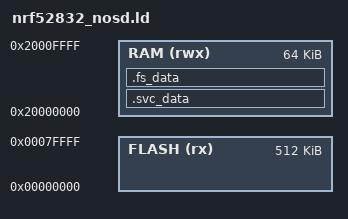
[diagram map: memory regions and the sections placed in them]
/* 无 SoftDevice / 无 bootloader：app 直接从 0x0 启动（nRF52832, 512KB/64KB） */

SEARCH_DIR(.)
GROUP(-lgcc -lc -lnosys)

MEMORY
{
  FLASH (rx) : ORIGIN = 0x00000000, LENGTH = 0x80000
  RAM  (rwx) : ORIGIN = 0x20000000, LENGTH = 0x10000
}

SECTIONS
{
  . = ALIGN(4);
  .svc_data :
  {
    PROVIDE(__start_svc_data = .);
    KEEP(*(.svc_data))
    PROVIDE(__stop_svc_data = .);
  } > RAM

  .fs_data :
  {
    PROVIDE(__start_fs_data = .);
    KEEP(*(.fs_data))
    PROVIDE(__stop_fs_data = .);
  } > RAM
} INSERT AFTER .data;

INCLUDE "nrf52_common.ld"
